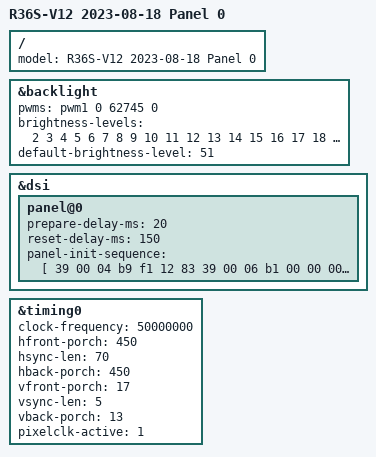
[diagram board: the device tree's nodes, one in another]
// SPDX-License-Identifier: GPL-2.0+
/* R35S / R36S-V12 2023-08-18 Panel 0 only. Host DTB probe; not boot-tested.
 * Base: Hardkernel RG351MP U-Boot DTS, GPL-2.0+ (5606e804ffe8f9e5427d55c8da04c638f01a9391).
 * Init sequence: (C) 2020 Hardkernel, rk3326-r35s-linux.dts, GPL-2.0+ OR MIT,
 * Linux d8402159c04b1044106b4f27b7ed7c22ed09228f. Bytes match the installed
 * U-Boot Panel 0 DTB. U-Boot timings/delays/PWM follow that separate DTB,
 * not the Linux display mode. See docs/archive/phase4/phase4-uboot-panel.md.
 */
#include "rg351mp-uboot.dts"

/ {
    model = "R36S-V12 2023-08-18 Panel 0";
};

&backlight {
    pwms = <&pwm1 0 62745 0>;
    brightness-levels = <
        2 3 4 5 6 7 8 9 10 11 12 13
        14 15 16 17 18 19 20 21 22 23 24 25
        26 27 28 29 30 31 32 33 34 35 36 37
        38 39 40 41 42 43 44 45 46 47 48 49
        50 51 52 53 54 55 56 57 58 59 60 61
        62 63 64 65 66 67 68 69 70 71 72 73
        74 75 76 77 78 79 80 81 82 83 84 85
        86 87 88 89 90 91 92 93 94 95 96 97
        98 99 100 101 102
    >;
    default-brightness-level = <51>;
};

&dsi {
    panel@0 {
        prepare-delay-ms = <20>;
        reset-delay-ms = <150>;
        panel-init-sequence = [
        39 00 04 b9 f1 12 83 39 00 06 b1 00
        00 00 da 80 39 00 04 b2 00 13 70 39
        00 0b b3 10 10 28 28 03 ff 00 00 00
        00 15 00 02 b4 80 15 00 03 b5 0a 0a
        15 00 03 b6 7f 7f 39 00 05 b8 26 62
        f0 63 39 00 1c ba 33 81 05 f9 0e 0e
        20 00 00 00 00 00 00 00 44 25 00 90
        0a 00 00 01 4f 01 00 00 37 15 00 02
        bc 47 39 00 04 bf 02 11 00 39 00 0a
        c0 73 73 50 50 00 00 12 50 00 39 00
        0d c1 53 c0 32 32 77 e1 dd dd 77 77
        33 33 39 00 07 c6 82 00 bf ff 00 ff
        39 00 07 c7 b8 00 0a 00 00 00 39 00
        05 c8 10 40 1e 02 15 00 02 cc 0b 39
        00 23 e0 00 07 0d 37 35 3f 41 44 06
        0c 0d 0f 11 10 12 14 1a 00 07 0d 37
        35 3f 41 44 06 0c 0d 0f 11 10 12 14
        1a 39 00 0f e3 07 07 0b 0b 0b 0b 00
        00 00 00 ff 00 c0 10 39 00 40 e9 c8
        10 02 00 00 b0 b1 11 31 23 28 80 b0
        b1 27 08 00 04 02 00 00 00 00 04 02
        00 00 00 88 88 ba 60 24 08 88 88 88
        88 88 88 88 ba 71 35 18 88 88 88 88
        88 00 00 00 01 00 00 00 00 00 00 00
        00 00 39 00 3e ea 97 0a 82 02 03 07
        00 00 00 00 00 00 81 88 ba 17 53 88
        88 88 88 88 88 80 88 ba 06 42 88 88
        88 88 88 88 23 00 00 02 80 00 00 00
        00 00 00 00 00 00 00 00 00 00 00 00
        00 00 00 00 00 00 00 39 00 04 ef ff
        ff 01 05 c8 01 11 05 32 01 29
        ];
    };
};

&timing0 {
    clock-frequency = <50000000>;
    hfront-porch = <450>;
    hsync-len = <70>;
    hback-porch = <450>;
    vfront-porch = <17>;
    vsync-len = <5>;
    vback-porch = <13>;
    pixelclk-active = <1>;
};
